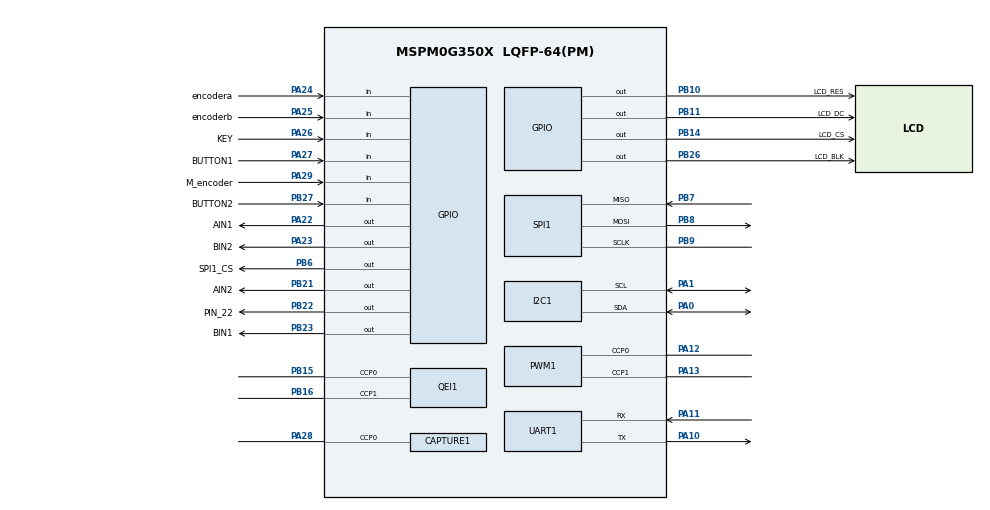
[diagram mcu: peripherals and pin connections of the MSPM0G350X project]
/**
 * @cliArgs --device "MSPM0G350X" --part "Default" --package "LQFP-64(PM)" --product "mspm0_sdk@2.10.00.04"
 * @versions {"tool":"1.27.1+4634"}
 */

/**
 * Import the modules used in this configuration.
 */
const CAPTURE  = scripting.addModule("/ti/driverlib/CAPTURE", {}, false);
const CAPTURE1 = CAPTURE.addInstance();
const DMA      = scripting.addModule("/ti/driverlib/DMA");
const GPIO     = scripting.addModule("/ti/driverlib/GPIO", {}, false);
const GPIO1    = GPIO.addInstance();
const GPIO2    = GPIO.addInstance();
const GPIO3    = GPIO.addInstance();
const GPIO4    = GPIO.addInstance();
const GPIO5    = GPIO.addInstance();
const GPIO6    = GPIO.addInstance();
const I2C      = scripting.addModule("/ti/driverlib/I2C", {}, false);
const I2C1     = I2C.addInstance();
const NONMAIN  = scripting.addModule("/ti/driverlib/NONMAIN");
const PWM      = scripting.addModule("/ti/driverlib/PWM", {}, false);
const PWM1     = PWM.addInstance();
const QEI      = scripting.addModule("/ti/driverlib/QEI", {}, false);
const QEI1     = QEI.addInstance();
const SPI      = scripting.addModule("/ti/driverlib/SPI", {}, false);
const SPI1     = SPI.addInstance();
const SYSCTL   = scripting.addModule("/ti/driverlib/SYSCTL");
const SYSTICK  = scripting.addModule("/ti/driverlib/SYSTICK");
const UART     = scripting.addModule("/ti/driverlib/UART", {}, false);
const UART1    = UART.addInstance();

/**
 * Write custom configuration values to the imported modules.
 */
const divider9       = system.clockTree["UDIV"];
divider9.divideValue = 2;

const mux2       = system.clockTree["CANCLKMUX"];
mux2.inputSelect = "CANCLKMUX_PLLCLK1_OUT";

const mux4       = system.clockTree["EXHFMUX"];
mux4.inputSelect = "EXHFMUX_XTAL";

const mux8       = system.clockTree["HSCLKMUX"];
mux8.inputSelect = "HSCLKMUX_SYSPLL2X";

const mux12       = system.clockTree["SYSPLLMUX"];
mux12.inputSelect = "zSYSPLLMUX_HFCLK";

const pinFunction4     = system.clockTree["HFXT"];
pinFunction4.inputFreq = 40;
pinFunction4.enable    = true;
pinFunction4.HFXTStartup = 10;

CAPTURE1.$name                              = "TB6612_ENB";
CAPTURE1.timerPeriod                        = "0.8ms";
CAPTURE1.event1ControllerInterruptEn        = ["CC0_DN_EVENT"];
CAPTURE1.event1PublisherChannel             = 1;
CAPTURE1.peripheral.$assign                 = "TIMG7";
CAPTURE1.peripheral.ccp0Pin.$assign         = "PA28";
CAPTURE1.ccp0PinConfig.hideOutputInversion  = scripting.forceWrite(false);
CAPTURE1.ccp0PinConfig.onlyInternalResistor = scripting.forceWrite(false);
CAPTURE1.ccp0PinConfig.passedPeripheralType = scripting.forceWrite("Digital");
CAPTURE1.ccp0PinConfig.$name                = "ti_driverlib_gpio_GPIOPinGeneric9";
CAPTURE1.ccp0PinConfig.enableConfig         = true;
CAPTURE1.ccp0PinConfig.internalResistor     = "PULL_UP";

const Board = scripting.addModule("/ti/driverlib/Board", {}, false);

DMA.subscriberIndex                             = ["1"];
DMA.sub1ChanID                                  = 1;
DMA.associatedChannels.create(1);
DMA.associatedChannels[0].$name                 = "DMA_CH0";
DMA.associatedChannels[0].triggerSelect         = "FSUB_1";
DMA.associatedChannels[0].addressMode           = "f2b";
DMA.associatedChannels[0].transferMode          = "FULL_CH_REPEAT_SINGLE";
DMA.associatedChannels[0].configureTransferSize = true;
DMA.associatedChannels[0].transferSize          = 256;

GPIO1.$name                         = "LED";
GPIO1.port                          = "PORTB";
GPIO1.associatedPins[0].ioStructure = "SD";
GPIO1.associatedPins[0].$name       = "PIN_22";
GPIO1.associatedPins[0].pin.$assign = "PB22";

GPIO2.$name                              = "ENCODER";
GPIO2.associatedPins.create(4);
GPIO2.associatedPins[0].$name            = "KEY";
GPIO2.associatedPins[0].direction        = "INPUT";
GPIO2.associatedPins[0].internalResistor = "PULL_UP";
GPIO2.associatedPins[0].assignedPort     = "PORTA";
GPIO2.associatedPins[0].pin.$assign      = "PA26";
GPIO2.associatedPins[1].$name            = "encodera";
GPIO2.associatedPins[1].direction        = "INPUT";
GPIO2.associatedPins[1].assignedPort     = "PORTA";
GPIO2.associatedPins[1].internalResistor = "PULL_UP";
GPIO2.associatedPins[1].pin.$assign      = "PA24";
GPIO2.associatedPins[2].$name            = "encoderb";
GPIO2.associatedPins[2].direction        = "INPUT";
GPIO2.associatedPins[2].internalResistor = "PULL_UP";
GPIO2.associatedPins[2].assignedPort     = "PORTA";
GPIO2.associatedPins[2].pin.$assign      = "PA25";
GPIO2.associatedPins[3].$name            = "M_encoder";
GPIO2.associatedPins[3].direction        = "INPUT";
GPIO2.associatedPins[3].internalResistor = "PULL_UP";
GPIO2.associatedPins[3].pin.$assign      = "PA29";

GPIO3.$name                         = "CS";
GPIO3.associatedPins[0].$name       = "SPI1_CS";
GPIO3.associatedPins[0].pin.$assign = "PB6";

GPIO4.$name                         = "LCD";
GPIO4.associatedPins.create(4);
GPIO4.associatedPins[0].$name       = "LCD_RES";
GPIO4.associatedPins[0].pin.$assign = "PB10";
GPIO4.associatedPins[1].$name       = "LCD_DC";
GPIO4.associatedPins[1].pin.$assign = "PB11";
GPIO4.associatedPins[2].$name       = "LCD_CS";
GPIO4.associatedPins[2].pin.$assign = "PB14";
GPIO4.associatedPins[3].$name       = "LCD_BLK";
GPIO4.associatedPins[3].pin.$assign = "PB26";

GPIO5.$name                              = "BUTTON";
GPIO5.associatedPins.create(2);
GPIO5.associatedPins[0].direction        = "INPUT";
GPIO5.associatedPins[0].internalResistor = "PULL_UP";
GPIO5.associatedPins[0].$name            = "BUTTON1";
GPIO5.associatedPins[0].pin.$assign      = "PA27";
GPIO5.associatedPins[1].$name            = "BUTTON2";
GPIO5.associatedPins[1].direction        = "INPUT";
GPIO5.associatedPins[1].pin.$assign      = "PB27";

GPIO6.$name                         = "TB6612";
GPIO6.associatedPins.create(4);
GPIO6.associatedPins[0].$name       = "AIN1";
GPIO6.associatedPins[0].pin.$assign = "PA22";
GPIO6.associatedPins[1].$name       = "AIN2";
GPIO6.associatedPins[1].pin.$assign = "PB21";
GPIO6.associatedPins[2].$name       = "BIN1";
GPIO6.associatedPins[2].pin.$assign = "PB23";
GPIO6.associatedPins[3].$name       = "BIN2";
GPIO6.associatedPins[3].pin.$assign = "PA23";

I2C1.$name                           = "I2C_0";
I2C1.basicEnableController           = true;
I2C1.basicControllerStandardBusSpeed = "Standard";
I2C1.peripheral.$assign              = "I2C0";
I2C1.peripheral.sdaPin.$assign       = "PA0";
I2C1.peripheral.sclPin.$assign       = "PA1";
I2C1.sdaPinConfig.$name              = "ti_driverlib_gpio_GPIOPinGeneric10";
I2C1.sclPinConfig.$name              = "ti_driverlib_gpio_GPIOPinGeneric11";

NONMAIN.nonmainWarning    = true;
NONMAIN.bslInvokePinCheck = false;

PWM1.$name                              = "DC_MOTOR";
PWM1.timerCount                         = 4000;
PWM1.timerStartTimer                    = true;
PWM1.pwmMode                            = "EDGE_ALIGN_UP";
PWM1.peripheral.$assign                 = "TIMG0";
PWM1.peripheral.ccp0Pin.$assign         = "PA12";
PWM1.peripheral.ccp1Pin.$assign         = "PA13";
PWM1.PWM_CHANNEL_0.$name                = "ti_driverlib_pwm_PWMTimerCC0";
PWM1.PWM_CHANNEL_1.$name                = "ti_driverlib_pwm_PWMTimerCC1";
PWM1.ccp0PinConfig.direction            = scripting.forceWrite("OUTPUT");
PWM1.ccp0PinConfig.hideOutputInversion  = scripting.forceWrite(false);
PWM1.ccp0PinConfig.onlyInternalResistor = scripting.forceWrite(false);
PWM1.ccp0PinConfig.passedPeripheralType = scripting.forceWrite("Digital");
PWM1.ccp0PinConfig.$name                = "ti_driverlib_gpio_GPIOPinGeneric5";
PWM1.ccp1PinConfig.direction            = scripting.forceWrite("OUTPUT");
PWM1.ccp1PinConfig.hideOutputInversion  = scripting.forceWrite(false);
PWM1.ccp1PinConfig.onlyInternalResistor = scripting.forceWrite(false);
PWM1.ccp1PinConfig.passedPeripheralType = scripting.forceWrite("Digital");
PWM1.ccp1PinConfig.$name                = "ti_driverlib_gpio_GPIOPinGeneric6";

QEI1.$name                              = "TB6612_ENA";
QEI1.peripheral.$assign                 = "TIMG8";
QEI1.peripheral.ccp0Pin.$assign         = "PB15";
QEI1.peripheral.ccp1Pin.$assign         = "PB16";
QEI1.ccp0PinConfig.hideOutputInversion  = scripting.forceWrite(false);
QEI1.ccp0PinConfig.onlyInternalResistor = scripting.forceWrite(false);
QEI1.ccp0PinConfig.passedPeripheralType = scripting.forceWrite("Digital");
QEI1.ccp0PinConfig.$name                = "ti_driverlib_gpio_GPIOPinGeneric7";
QEI1.ccp0PinConfig.enableConfig         = true;
QEI1.ccp0PinConfig.internalResistor     = "PULL_UP";
QEI1.ccp1PinConfig.hideOutputInversion  = scripting.forceWrite(false);
QEI1.ccp1PinConfig.onlyInternalResistor = scripting.forceWrite(false);
QEI1.ccp1PinConfig.passedPeripheralType = scripting.forceWrite("Digital");
QEI1.ccp1PinConfig.$name                = "ti_driverlib_gpio_GPIOPinGeneric8";

SPI1.$name                              = "W25Q64";
SPI1.frameFormat                        = "MOTO3";
SPI1.sclkPinConfig.direction            = scripting.forceWrite("OUTPUT");
SPI1.sclkPinConfig.onlyInternalResistor = scripting.forceWrite(false);
SPI1.sclkPinConfig.passedPeripheralType = scripting.forceWrite("Digital");
SPI1.sclkPinConfig.$name                = "ti_driverlib_gpio_GPIOPinGeneric2";
SPI1.mosiPinConfig.direction            = scripting.forceWrite("OUTPUT");
SPI1.mosiPinConfig.hideOutputInversion  = scripting.forceWrite(false);
SPI1.mosiPinConfig.onlyInternalResistor = scripting.forceWrite(false);
SPI1.mosiPinConfig.passedPeripheralType = scripting.forceWrite("Digital");
SPI1.mosiPinConfig.$name                = "ti_driverlib_gpio_GPIOPinGeneric3";
SPI1.misoPinConfig.onlyInternalResistor = scripting.forceWrite(false);
SPI1.misoPinConfig.passedPeripheralType = scripting.forceWrite("Digital");
SPI1.misoPinConfig.$name                = "ti_driverlib_gpio_GPIOPinGeneric4";
SPI1.peripheral.$assign                 = "SPI1";
SPI1.peripheral.sclkPin.$assign         = "PB9";
SPI1.peripheral.mosiPin.$assign         = "PB8";
SPI1.peripheral.misoPin.$assign         = "PB7";

SYSCTL.clockTreeEn     = true;
SYSCTL.useHFCLK_Manual = true;
SYSCTL.HFCLKSource     = "HFXT";
SYSCTL.HFCLKMonitor    = true;
SYSCTL.HFCLK_Freq      = 40000000;
SYSCTL.HFXTStartup     = 10;

SYSTICK.periodEnable      = true;
SYSTICK.interruptEnable   = true;
SYSTICK.period            = 80000;
SYSTICK.interruptPriority = "3";
SYSTICK.systickEnable     = true;

UART1.$name                            = "sys_uart";
UART1.targetBaudRate                   = 115200;
UART1.peripheral.rxPin.$assign         = "PA11";
UART1.peripheral.txPin.$assign         = "PA10";
UART1.txPinConfig.direction            = scripting.forceWrite("OUTPUT");
UART1.txPinConfig.hideOutputInversion  = scripting.forceWrite(false);
UART1.txPinConfig.onlyInternalResistor = scripting.forceWrite(false);
UART1.txPinConfig.passedPeripheralType = scripting.forceWrite("Digital");
UART1.txPinConfig.$name                = "ti_driverlib_gpio_GPIOPinGeneric0";
UART1.txPinConfig.enableConfig         = true;
UART1.rxPinConfig.hideOutputInversion  = scripting.forceWrite(false);
UART1.rxPinConfig.onlyInternalResistor = scripting.forceWrite(false);
UART1.rxPinConfig.passedPeripheralType = scripting.forceWrite("Digital");
UART1.rxPinConfig.$name                = "ti_driverlib_gpio_GPIOPinGeneric1";
UART1.rxPinConfig.enableConfig         = true;

/**
 * Pinmux solution for unlocked pins/peripherals. This ensures that minor changes to the automatic solver in a future
 * version of the tool will not impact the pinmux you originally saw.  These lines can be completely deleted in order to
 * re-solve from scratch.
 */
pinFunction4.peripheral.$suggestSolution              = "SYSCTL";
pinFunction4.peripheral.hfxInPin.$suggestSolution     = "PA5";
pinFunction4.peripheral.hfxOutPin.$suggestSolution    = "PA6";
Board.peripheral.$suggestSolution                     = "DEBUGSS";
Board.peripheral.swclkPin.$suggestSolution            = "PA20";
Board.peripheral.swdioPin.$suggestSolution            = "PA19";
DMA.associatedChannels[0].peripheral.$suggestSolution = "DMA_CH0";
UART1.peripheral.$suggestSolution                     = "UART0";
